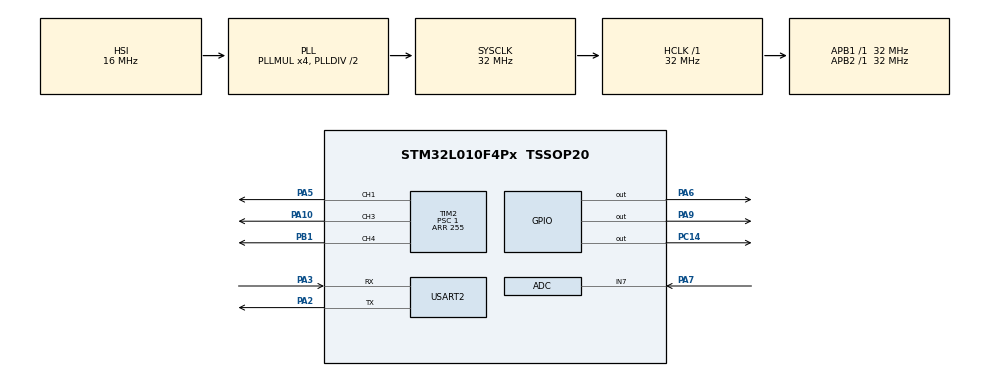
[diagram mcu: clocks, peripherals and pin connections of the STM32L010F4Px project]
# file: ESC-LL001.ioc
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Mcu.Family=STM32L0
Mcu.Name=STM32L010F4Px
Mcu.Package=TSSOP20
NVIC.TIM2_IRQn=true\:0\:0\:false\:false\:true\:true\:true
PA10.Signal=S_TIM2_CH3
PA13.Mode=Serial_Wire
PA13.Signal=SYS_SWDIO
PA14.Mode=Serial_Wire
PA14.Signal=SYS_SWCLK
PA2.Mode=Asynchronous
PA2.Signal=USART2_TX
PA3.Mode=Asynchronous
PA3.Signal=USART2_RX
PA5.Signal=S_TIM2_CH1
PA6.Signal=GPIO_Output
PA7.Mode=IN7
PA7.Signal=ADC_IN7
PA9.Signal=GPIO_Output
PB1.Signal=S_TIM2_CH4
PC14-OSC32_IN.Signal=GPIO_Output
ProjectManager.HeapSize=0x200
ProjectManager.StackSize=0x400
ProjectManager.TargetToolchain=STM32CubeIDE
RCC.AHBFreq_Value=32000000
RCC.APB1Freq_Value=32000000
RCC.APB1TimFreq_Value=32000000
RCC.APB2Freq_Value=32000000
RCC.APB2TimFreq_Value=32000000
RCC.HCLKFreq_Value=32000000
RCC.HSE_VALUE=8000000
RCC.HSI16_VALUE=16000000
RCC.HSI_VALUE=16000000
RCC.LSE_VALUE=32768
RCC.MSI_VALUE=2097000
RCC.PLLMUL=RCC_PLLMUL_4
RCC.SYSCLKFreq_VALUE=32000000
RCC.SYSCLKSource=RCC_SYSCLKSOURCE_PLLCLK
RCC.VCOOutputFreq_Value=64000000
SH.S_TIM2_CH1.0=TIM2_CH1,PWM Generation1 CH1
SH.S_TIM2_CH3.0=TIM2_CH3,PWM Generation3 CH3
SH.S_TIM2_CH4.0=TIM2_CH4,PWM Generation4 CH4
TIM2.AutoReloadPreload=TIM_AUTORELOAD_PRELOAD_ENABLE
TIM2.Channel-PWM\ Generation1\ CH1=TIM_CHANNEL_1
TIM2.Channel-PWM\ Generation3\ CH3=TIM_CHANNEL_3
TIM2.Channel-PWM\ Generation4\ CH4=TIM_CHANNEL_4
TIM2.OC1Preload_PWM=DISABLE
TIM2.OC3Preload_PWM=DISABLE
TIM2.OC4Preload_PWM=DISABLE
TIM2.Period=255
TIM2.Prescaler=1
USART2.VirtualMode=VM_ASYNC
board=custom

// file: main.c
/* USER CODE BEGIN Header */
/**
 ******************************************************************************
 * @file           : main.c
 * @brief          : Main program body
 ******************************************************************************
 * @attention
 *
 * <h2><center>&copy; Copyright (c) 2021 STMicroelectronics.
 * All rights reserved.</center></h2>
 *
 * This software component is licensed by ST under BSD 3-Clause license,
 * the "License"; You may not use this file except in compliance with the
 * License. You may obtain a copy of the License at:
 *                        opensource.org/licenses/BSD-3-Clause
 *
 ******************************************************************************
 */
/* USER CODE END Header */
#include "main.h"

/* USER CODE BEGIN Includes */
//#include "math.h"

/* USER CODE END Includes */

ADC_HandleTypeDef hadc;

UART_HandleTypeDef huart2;

void SystemClock_Config(void);
static void MX_GPIO_Init(void);
static void MX_TIM2_Init(void);
static void MX_ADC_Init(void);
static void MX_USART2_UART_Init(void);

/* USER CODE BEGIN 0 */
#include "ESC.h"
/* USER CODE END 0 */

int main(void)
{

  /* MCU Configuration--------------------------------------------------------*/

  /* Reset of all peripherals, Initializes the Flash interface and the Systick. */
  HAL_Init();

  /* Configure the system clock */
  SystemClock_Config();

  /* Initialize all configured peripherals */
  MX_GPIO_Init();
  MX_TIM2_Init();
  MX_ADC_Init();
  MX_USART2_UART_Init();
  /* USER CODE BEGIN 2 */
//  HAL_TIM_Base_Start_IT(&htim2);
  LL_TIM_EnableCounter(TIM2);
  LL_TIM_CC_EnableChannel(TIM2, LL_TIM_CHANNEL_CH3);
  LL_TIM_CC_EnableChannel(TIM2, LL_TIM_CHANNEL_CH4);
  LL_TIM_CC_EnableChannel(TIM2, LL_TIM_CHANNEL_CH1);

  ESC_initialize();
  /* USER CODE END 2 */

  /* Infinite loop */
  /* USER CODE BEGIN WHILE */
	while (1) {
		ESC_Drive();
    /* USER CODE END WHILE */

	}
}

void SystemClock_Config(void)
{
  RCC_OscInitTypeDef RCC_OscInitStruct = {0};
  RCC_ClkInitTypeDef RCC_ClkInitStruct = {0};
  RCC_PeriphCLKInitTypeDef PeriphClkInit = {0};

  /** Configure the main internal regulator output voltage
  */
  __HAL_PWR_VOLTAGESCALING_CONFIG(PWR_REGULATOR_VOLTAGE_SCALE1);
  /** Initializes the RCC Oscillators according to the specified parameters
  * in the RCC_OscInitTypeDef structure.
  */
  RCC_OscInitStruct.OscillatorType = RCC_OSCILLATORTYPE_HSI;
  RCC_OscInitStruct.HSIState = RCC_HSI_ON;
  RCC_OscInitStruct.HSICalibrationValue = RCC_HSICALIBRATION_DEFAULT;
  RCC_OscInitStruct.PLL.PLLState = RCC_PLL_ON;
  RCC_OscInitStruct.PLL.PLLSource = RCC_PLLSOURCE_HSI;
  RCC_OscInitStruct.PLL.PLLMUL = RCC_PLLMUL_4;
  RCC_OscInitStruct.PLL.PLLDIV = RCC_PLLDIV_2;
  if (HAL_RCC_OscConfig(&RCC_OscInitStruct) != HAL_OK)
  {
    Error_Handler();
  }
  /** Initializes the CPU, AHB and APB buses clocks
  */
  RCC_ClkInitStruct.ClockType = RCC_CLOCKTYPE_HCLK|RCC_CLOCKTYPE_SYSCLK
                              |RCC_CLOCKTYPE_PCLK1|RCC_CLOCKTYPE_PCLK2;
  RCC_ClkInitStruct.SYSCLKSource = RCC_SYSCLKSOURCE_PLLCLK;
  RCC_ClkInitStruct.AHBCLKDivider = RCC_SYSCLK_DIV1;
  RCC_ClkInitStruct.APB1CLKDivider = RCC_HCLK_DIV1;
  RCC_ClkInitStruct.APB2CLKDivider = RCC_HCLK_DIV1;

  if (HAL_RCC_ClockConfig(&RCC_ClkInitStruct, FLASH_LATENCY_1) != HAL_OK)
  {
    Error_Handler();
  }
  PeriphClkInit.PeriphClockSelection = RCC_PERIPHCLK_USART2;
  PeriphClkInit.Usart2ClockSelection = RCC_USART2CLKSOURCE_PCLK1;
  if (HAL_RCCEx_PeriphCLKConfig(&PeriphClkInit) != HAL_OK)
  {
    Error_Handler();
  }
}

static void MX_ADC_Init(void)
{

  ADC_ChannelConfTypeDef sConfig = {0};

  /** Configure the global features of the ADC (Clock, Resolution, Data Alignment and number of conversion)
  */
  hadc.Instance = ADC1;
  hadc.Init.OversamplingMode = DISABLE;
  hadc.Init.ClockPrescaler = ADC_CLOCK_SYNC_PCLK_DIV2;
  hadc.Init.Resolution = ADC_RESOLUTION_12B;
  hadc.Init.SamplingTime = ADC_SAMPLETIME_1CYCLE_5;
  hadc.Init.ScanConvMode = ADC_SCAN_DIRECTION_FORWARD;
  hadc.Init.DataAlign = ADC_DATAALIGN_RIGHT;
  hadc.Init.ContinuousConvMode = DISABLE;
  hadc.Init.DiscontinuousConvMode = DISABLE;
  hadc.Init.ExternalTrigConvEdge = ADC_EXTERNALTRIGCONVEDGE_NONE;
  hadc.Init.ExternalTrigConv = ADC_SOFTWARE_START;
  hadc.Init.DMAContinuousRequests = DISABLE;
  hadc.Init.EOCSelection = ADC_EOC_SINGLE_CONV;
  hadc.Init.Overrun = ADC_OVR_DATA_PRESERVED;
  hadc.Init.LowPowerAutoWait = DISABLE;
  hadc.Init.LowPowerFrequencyMode = DISABLE;
  hadc.Init.LowPowerAutoPowerOff = DISABLE;
  if (HAL_ADC_Init(&hadc) != HAL_OK)
  {
    Error_Handler();
  }
  /** Configure for the selected ADC regular channel to be converted.
  */
  sConfig.Channel = ADC_CHANNEL_7;
  sConfig.Rank = ADC_RANK_CHANNEL_NUMBER;
  if (HAL_ADC_ConfigChannel(&hadc, &sConfig) != HAL_OK)
  {
    Error_Handler();
  }

}

static void MX_TIM2_Init(void)
{

  LL_TIM_InitTypeDef TIM_InitStruct = {0};
  LL_TIM_OC_InitTypeDef TIM_OC_InitStruct = {0};

  LL_GPIO_InitTypeDef GPIO_InitStruct = {0};

  /* Peripheral clock enable */
  LL_APB1_GRP1_EnableClock(LL_APB1_GRP1_PERIPH_TIM2);

  /* TIM2 interrupt Init */
  NVIC_SetPriority(TIM2_IRQn, 0);
  NVIC_EnableIRQ(TIM2_IRQn);

  TIM_InitStruct.Prescaler = 1;
  TIM_InitStruct.CounterMode = LL_TIM_COUNTERMODE_UP;
  TIM_InitStruct.Autoreload = 255;
  TIM_InitStruct.ClockDivision = LL_TIM_CLOCKDIVISION_DIV1;
  LL_TIM_Init(TIM2, &TIM_InitStruct);
  LL_TIM_EnableARRPreload(TIM2);
  LL_TIM_OC_EnablePreload(TIM2, LL_TIM_CHANNEL_CH1);
  TIM_OC_InitStruct.OCMode = LL_TIM_OCMODE_PWM1;
  TIM_OC_InitStruct.OCState = LL_TIM_OCSTATE_DISABLE;
  TIM_OC_InitStruct.CompareValue = 0;
  TIM_OC_InitStruct.OCPolarity = LL_TIM_OCPOLARITY_HIGH;
  LL_TIM_OC_Init(TIM2, LL_TIM_CHANNEL_CH1, &TIM_OC_InitStruct);
  LL_TIM_OC_DisableFast(TIM2, LL_TIM_CHANNEL_CH1);
  LL_TIM_OC_EnablePreload(TIM2, LL_TIM_CHANNEL_CH3);
  LL_TIM_OC_Init(TIM2, LL_TIM_CHANNEL_CH3, &TIM_OC_InitStruct);
  LL_TIM_OC_DisableFast(TIM2, LL_TIM_CHANNEL_CH3);
  LL_TIM_OC_EnablePreload(TIM2, LL_TIM_CHANNEL_CH4);
  LL_TIM_OC_Init(TIM2, LL_TIM_CHANNEL_CH4, &TIM_OC_InitStruct);
  LL_TIM_OC_DisableFast(TIM2, LL_TIM_CHANNEL_CH4);
  LL_TIM_SetTriggerOutput(TIM2, LL_TIM_TRGO_RESET);
  LL_TIM_DisableMasterSlaveMode(TIM2);
  LL_TIM_OC_DisablePreload(TIM2, LL_TIM_CHANNEL_CH1);
  LL_TIM_OC_DisablePreload(TIM2, LL_TIM_CHANNEL_CH3);
  LL_TIM_OC_DisablePreload(TIM2, LL_TIM_CHANNEL_CH4);
  LL_IOP_GRP1_EnableClock(LL_IOP_GRP1_PERIPH_GPIOA);
  LL_IOP_GRP1_EnableClock(LL_IOP_GRP1_PERIPH_GPIOB);
  /**TIM2 GPIO Configuration
  PA5   ------> TIM2_CH1
  PB1   ------> TIM2_CH4
  PA10   ------> TIM2_CH3
  */
  GPIO_InitStruct.Pin = LL_GPIO_PIN_5;
  GPIO_InitStruct.Mode = LL_GPIO_MODE_ALTERNATE;
  GPIO_InitStruct.Speed = LL_GPIO_SPEED_FREQ_LOW;
  GPIO_InitStruct.OutputType = LL_GPIO_OUTPUT_PUSHPULL;
  GPIO_InitStruct.Pull = LL_GPIO_PULL_NO;
  GPIO_InitStruct.Alternate = LL_GPIO_AF_5;
  LL_GPIO_Init(GPIOA, &GPIO_InitStruct);

  GPIO_InitStruct.Pin = LL_GPIO_PIN_1;
  GPIO_InitStruct.Mode = LL_GPIO_MODE_ALTERNATE;
  GPIO_InitStruct.Speed = LL_GPIO_SPEED_FREQ_LOW;
  GPIO_InitStruct.OutputType = LL_GPIO_OUTPUT_PUSHPULL;
  GPIO_InitStruct.Pull = LL_GPIO_PULL_NO;
  GPIO_InitStruct.Alternate = LL_GPIO_AF_5;
  LL_GPIO_Init(GPIOB, &GPIO_InitStruct);

  GPIO_InitStruct.Pin = LL_GPIO_PIN_10;
  GPIO_InitStruct.Mode = LL_GPIO_MODE_ALTERNATE;
  GPIO_InitStruct.Speed = LL_GPIO_SPEED_FREQ_LOW;
  GPIO_InitStruct.OutputType = LL_GPIO_OUTPUT_PUSHPULL;
  GPIO_InitStruct.Pull = LL_GPIO_PULL_NO;
  GPIO_InitStruct.Alternate = LL_GPIO_AF_5;
  LL_GPIO_Init(GPIOA, &GPIO_InitStruct);

}

static void MX_USART2_UART_Init(void)
{

  huart2.Instance = USART2;
  huart2.Init.BaudRate = 115200;
  huart2.Init.WordLength = UART_WORDLENGTH_8B;
  huart2.Init.StopBits = UART_STOPBITS_1;
  huart2.Init.Parity = UART_PARITY_NONE;
  huart2.Init.Mode = UART_MODE_TX_RX;
  huart2.Init.HwFlowCtl = UART_HWCONTROL_NONE;
  huart2.Init.OverSampling = UART_OVERSAMPLING_16;
  huart2.Init.OneBitSampling = UART_ONE_BIT_SAMPLE_DISABLE;
  huart2.AdvancedInit.AdvFeatureInit = UART_ADVFEATURE_NO_INIT;
  if (HAL_UART_Init(&huart2) != HAL_OK)
  {
    Error_Handler();
  }

}

static void MX_GPIO_Init(void)
{
  LL_GPIO_InitTypeDef GPIO_InitStruct = {0};

  /* GPIO Ports Clock Enable */
  LL_IOP_GRP1_EnableClock(LL_IOP_GRP1_PERIPH_GPIOC);
  LL_IOP_GRP1_EnableClock(LL_IOP_GRP1_PERIPH_GPIOA);
  LL_IOP_GRP1_EnableClock(LL_IOP_GRP1_PERIPH_GPIOB);

  /**/
  LL_GPIO_ResetOutputPin(GPIOC, LL_GPIO_PIN_14);

  /**/
  LL_GPIO_ResetOutputPin(GPIOA, LL_GPIO_PIN_6);

  /**/
  LL_GPIO_ResetOutputPin(GPIOA, LL_GPIO_PIN_9);

  /**/
  GPIO_InitStruct.Pin = LL_GPIO_PIN_14;
  GPIO_InitStruct.Mode = LL_GPIO_MODE_OUTPUT;
  GPIO_InitStruct.Speed = LL_GPIO_SPEED_FREQ_LOW;
  GPIO_InitStruct.OutputType = LL_GPIO_OUTPUT_PUSHPULL;
  GPIO_InitStruct.Pull = LL_GPIO_PULL_NO;
  LL_GPIO_Init(GPIOC, &GPIO_InitStruct);

  /**/
  GPIO_InitStruct.Pin = LL_GPIO_PIN_6;
  GPIO_InitStruct.Mode = LL_GPIO_MODE_OUTPUT;
  GPIO_InitStruct.Speed = LL_GPIO_SPEED_FREQ_LOW;
  GPIO_InitStruct.OutputType = LL_GPIO_OUTPUT_PUSHPULL;
  GPIO_InitStruct.Pull = LL_GPIO_PULL_NO;
  LL_GPIO_Init(GPIOA, &GPIO_InitStruct);

  /**/
  GPIO_InitStruct.Pin = LL_GPIO_PIN_9;
  GPIO_InitStruct.Mode = LL_GPIO_MODE_OUTPUT;
  GPIO_InitStruct.Speed = LL_GPIO_SPEED_FREQ_LOW;
  GPIO_InitStruct.OutputType = LL_GPIO_OUTPUT_PUSHPULL;
  GPIO_InitStruct.Pull = LL_GPIO_PULL_NO;
  LL_GPIO_Init(GPIOA, &GPIO_InitStruct);

}

void Error_Handler(void)
{
	__disable_irq();
	while (1) {
	}
}

/************************ (C) COPYRIGHT STMicroelectronics *****END OF FILE****/
